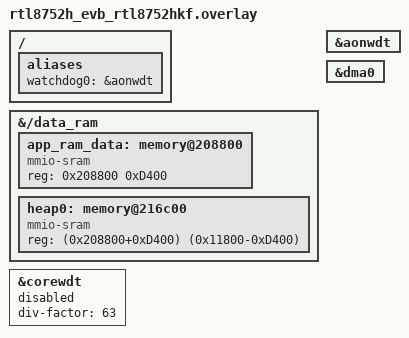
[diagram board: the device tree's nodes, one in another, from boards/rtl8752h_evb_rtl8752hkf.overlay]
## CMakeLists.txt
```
# SPDX-License-Identifier: Apache-2.0

cmake_minimum_required(VERSION 3.20.0)

find_package(Zephyr REQUIRED HINTS $ENV{ZEPHYR_BASE})
project(peripheral_ota)

target_sources(app PRIVATE src/main.c)

target_include_directories(app PRIVATE inc)
```

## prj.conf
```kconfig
# BT
CONFIG_BT=y
CONFIG_BT_SMP=y
CONFIG_BT_FIXED_PASSKEY=y
CONFIG_BT_PERIPHERAL=y
CONFIG_BT_DEVICE_NAME="Zephyr OTA"
# OTA needs more memory on BT_RX_THREAD
CONFIG_BT_RX_STACK_SIZE=1792
CONFIG_BT_KEYS_OVERWRITE_OLDEST=y
CONFIG_BT_SETTINGS=y

CONFIG_FLASH=y
CONFIG_FLASH_MAP=y
CONFIG_NVS=y
CONFIG_SETTINGS=y

CONFIG_KERNEL_MEM_POOL=y
CONFIG_HEAP_MEM_POOL_SIZE=1024

# Logging and Debugging
CONFIG_LOG=y
CONFIG_ASSERT=y
CONFIG_LOG_FUNC_NAME_PREFIX_DBG=y
CONFIG_REALTEK_OTA_LOG_LEVEL_DBG=y
CONFIG_REALTEK_DFU_LOG_LEVEL_DBG=y
CONFIG_SYS_HEAP_RUNTIME_STATS=y
CONFIG_LOG_BUFFER_SIZE=3072

CONFIG_REALTEK_OTA=y
```

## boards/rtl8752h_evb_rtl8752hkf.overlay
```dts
/*
 * Copyright (c) 2025 Realtek Semiconductor Corp.
 *
 * SPDX-License-Identifier: Apache-2.0
 */

/ {
	aliases {
		watchdog0 = &aonwdt;
	};
};

&{/data_ram} {
	#address-cells = < 0x1 >;
	#size-cells = < 0x1 >;
	app_ram_data: memory@208800 {
		compatible = "mmio-sram";
		reg = < 0x208800 0xD400 >;
	};
	heap0: memory@216c00 {
		compatible = "mmio-sram";
		reg = < (0x208800+0xD400) (0x11800-0xD400) >;
	};
};

&corewdt {
	status = "disabled";
	div-factor = <63>;
};

&aonwdt {
	status = "okay";
};

&dma0 {
	status = "okay";
};
```

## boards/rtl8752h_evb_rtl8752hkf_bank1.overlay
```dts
/*
 * Copyright (c) 2025 Realtek Semiconductor Corp.
 *
 * SPDX-License-Identifier: Apache-2.0
 */
/delete-node/ &app_partition;

&flash {
	partitions {
		app_partition: partition@92000 {
			label = "app-image";
			reg = <0x92000 (DT_SIZE_K(500))>;
		};
	};
};
```

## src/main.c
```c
/*
 * Copyright (c) 2025 Realtek Semiconductor Corp.
 *
 * SPDX-License-Identifier: Apache-2.0
 */

#include <zephyr/types.h>
#include <string.h>
#include <errno.h>
#include <zephyr/sys/printk.h>
#include <zephyr/kernel.h>
#include <zephyr/settings/settings.h>
#include <zephyr/bluetooth/bluetooth.h>
#include <zephyr/bluetooth/conn.h>
#include <zephyr/bluetooth/gatt.h>
#include <zephyr/bluetooth/services/ots.h>

#include <patch_header_check.h>

#include <zephyr/logging/log.h>

LOG_MODULE_REGISTER(main, LOG_LEVEL_DBG);

#define DEVICE_NAME     CONFIG_BT_DEVICE_NAME
#define DEVICE_NAME_LEN (sizeof(DEVICE_NAME) - 1)

static const struct bt_data ad[] =
{
    BT_DATA_BYTES(BT_DATA_FLAGS, (BT_LE_AD_GENERAL | BT_LE_AD_NO_BREDR)),
    BT_DATA(BT_DATA_NAME_COMPLETE, DEVICE_NAME, DEVICE_NAME_LEN),
};

static const struct bt_data sd[] =
{
    BT_DATA(BT_DATA_NAME_COMPLETE, DEVICE_NAME, DEVICE_NAME_LEN),
};

static void connected(struct bt_conn *conn, uint8_t err)
{
    if (err)
    {
        printk("Connection failed (err %u)\n", err);
        return;
    }

    printk("Connected\n");
}

BT_CONN_CB_DEFINE(conn_callbacks) =
{
    .connected = connected,
};

static void auth_passkey_display(struct bt_conn *conn, unsigned int passkey)
{
    char addr[BT_ADDR_LE_STR_LEN];

    bt_addr_le_to_str(bt_conn_get_dst(conn), addr, sizeof(addr));

    printk("Passkey for %s: %06u\n", addr, passkey);
}

static void auth_cancel(struct bt_conn *conn)
{
    char addr[BT_ADDR_LE_STR_LEN];

    bt_addr_le_to_str(bt_conn_get_dst(conn), addr, sizeof(addr));

    printk("Pairing cancelled: %s\n", addr);
}

static struct bt_conn_auth_cb auth_cb_display =
{
    .passkey_display = auth_passkey_display,
    .passkey_entry = NULL,
    .cancel = auth_cancel,
};

int main(void)
{
    int err;

    if (is_ota_support_bank_switch())
    {
        printk("Starting Bluetooth Peripheral OTA-Dual-Bank Example\n");
    }
    else
    {
        printk("Starting Bluetooth Peripheral OTA-Single-Bank Example\n");
    }

    printk("CONFIG_FLASH_LOAD_OFFSET=0x%x\n", CONFIG_FLASH_LOAD_OFFSET);

    err = bt_enable(NULL);
    if (err)
    {
        printk("Bluetooth init failed (err %d)\n", err);
        return 0;
    }

    printk("Bluetooth initialized\n");

    bt_passkey_set(232323);
    bt_conn_auth_cb_register(&auth_cb_display);

    if (IS_ENABLED(CONFIG_SETTINGS))
    {
        settings_load();
    }

    err = bt_le_adv_start(BT_LE_ADV_CONN, ad, ARRAY_SIZE(ad), sd, ARRAY_SIZE(sd));
    if (err)
    {
        printk("Advertising failed to start (err %d)\n", err);
        return 0;
    }
    printk("Advertising successfully started\n");

    return 0;
}
```
